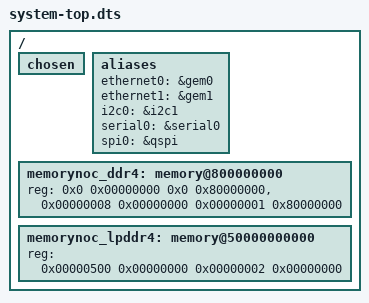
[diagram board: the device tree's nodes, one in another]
/*
 * CAUTION: This file is automatically generated by Xilinx.
 * Version:  
 * Today is: Fri Jun 11 15:16:47 2021
 */


/dts-v1/;
#include "versal.dtsi"
#include "versal-vck190-reva-x-ebm-01-reva.dtsi"
#include "versal-clk.dtsi"
#include "pl.dtsi"
#include "pcw.dtsi"
/ {
	chosen {
	};
	aliases {
		ethernet0 = &gem0;
		ethernet1 = &gem1;
		i2c0 = &i2c1;
		serial0 = &serial0;
		spi0 = &qspi;
	};
	memorynoc_ddr4: memory@800000000 {
		device_type = "memory";
		reg = <0x0 0x00000000 0x0 0x80000000>, <0x00000008 0x00000000 0x00000001 0x80000000>;
	};
	memorynoc_lpddr4: memory@50000000000 {
		device_type = "memory";
		reg = <0x00000500 0x00000000 0x00000002 0x00000000>;
	};
};
#include "system-user.dtsi"
